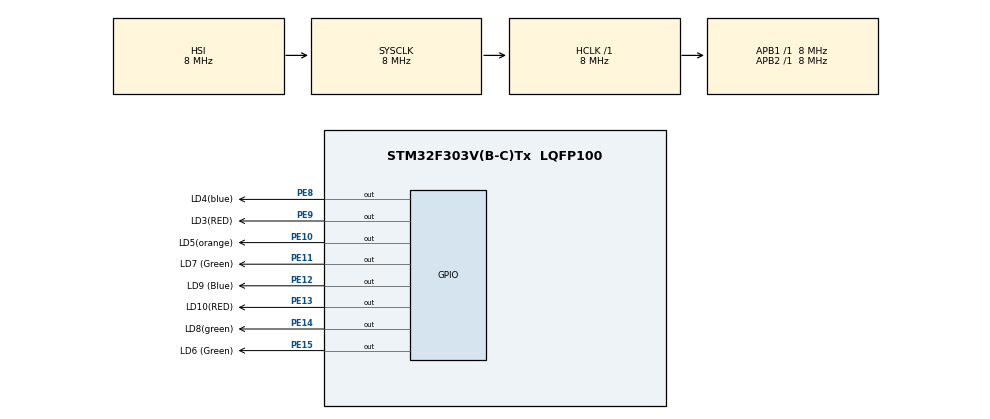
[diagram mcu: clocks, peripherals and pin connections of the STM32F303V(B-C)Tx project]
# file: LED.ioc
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Mcu.Family=STM32F3
Mcu.Name=STM32F303V(B-C)Tx
Mcu.Package=LQFP100
NVIC.PriorityGroup=NVIC_PRIORITYGROUP_4
PE10.GPIO_Label=LD5(orange)
PE10.Signal=GPIO_Output
PE11.GPIO_Label=LD7 (Green)
PE11.Signal=GPIO_Output
PE12.GPIO_Label=LD9 (Blue)
PE12.Signal=GPIO_Output
PE13.GPIO_Label=LD10(RED)
PE13.Signal=GPIO_Output
PE14.GPIO_Label=LD8(green)
PE14.Signal=GPIO_Output
PE15.GPIO_Label=LD6 (Green)
PE15.Signal=GPIO_Output
PE8.GPIO_Label=LD4(blue)
PE8.Signal=GPIO_Output
PE9.GPIO_Label=LD3(RED)
PE9.Signal=GPIO_Output
ProjectManager.HeapSize=0x200
ProjectManager.StackSize=0x400
ProjectManager.TargetToolchain=STM32CubeIDE
RCC.AHBFreq_Value=8000000
RCC.APB1Freq_Value=8000000
RCC.APB2Freq_Value=8000000
RCC.CortexFreq_Value=8000000
RCC.HSE_VALUE=8000000
RCC.HSI_VALUE=8000000
RCC.LSE_VALUE=32768
RCC.SYSCLKFreq_VALUE=8000000
board=custom

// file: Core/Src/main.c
/* USER CODE BEGIN Header */
/**
  ******************************************************************************
  * @file           : main.c
  * @brief          : Main program body
  ******************************************************************************
  * @attention
  *
  * Copyright (c) 2024 STMicroelectronics.
  * All rights reserved.
  *
  * This software is licensed under terms that can be found in the LICENSE file
  * in the root directory of this software component.
  * If no LICENSE file comes with this software, it is provided AS-IS.
  *
  ******************************************************************************
  */
/* USER CODE END Header */
#include "main.h"

void SystemClock_Config(void);
static void MX_GPIO_Init(void);

int main(void)
{
  /* USER CODE BEGIN 1 */
	GPIO_TypeDef* ledPorts[] = {LD3_GPIO_Port, LD4_GPIO_Port, LD6_GPIO_Port, LD8_GPIO_Port, LD10_GPIO_Port, LD9_GPIO_Port, LD7_GPIO_Port, LD5_GPIO_Port};
	    uint16_t ledPins[] = {LD3_Pin, LD4_Pin, LD6_Pin, LD8_Pin, LD10_Pin, LD9_Pin, LD7_Pin, LD5_Pin};

	    int numLeds = sizeof(ledPorts) / sizeof(ledPorts[0]);
  /* USER CODE END 1 */

  /* MCU Configuration--------------------------------------------------------*/

  /* Reset of all peripherals, Initializes the Flash interface and the Systick. */
  HAL_Init();

  /* Configure the system clock */
  SystemClock_Config();

  /* Initialize all configured peripherals */
  MX_GPIO_Init();

  /* Infinite loop */
  while (1)
  {

    /* USER CODE BEGIN 3 */
	  for (int i = 0; i < numLeds; ++i)
	         {
	             HAL_GPIO_TogglePin(ledPorts[i], ledPins[i]);
	             HAL_Delay(500);
	             HAL_GPIO_TogglePin(ledPorts[i], ledPins[i]);  // Turn off the current LED
	             HAL_Delay(500);
	         }
  }
  /* USER CODE END 3 */
}

void SystemClock_Config(void)
{
  RCC_OscInitTypeDef RCC_OscInitStruct = {0};
  RCC_ClkInitTypeDef RCC_ClkInitStruct = {0};

  /** Initializes the RCC Oscillators according to the specified parameters
  * in the RCC_OscInitTypeDef structure.
  */
  RCC_OscInitStruct.OscillatorType = RCC_OSCILLATORTYPE_HSI;
  RCC_OscInitStruct.HSIState = RCC_HSI_ON;
  RCC_OscInitStruct.HSICalibrationValue = RCC_HSICALIBRATION_DEFAULT;
  RCC_OscInitStruct.PLL.PLLState = RCC_PLL_NONE;
  if (HAL_RCC_OscConfig(&RCC_OscInitStruct) != HAL_OK)
  {
    Error_Handler();
  }

  /** Initializes the CPU, AHB and APB buses clocks
  */
  RCC_ClkInitStruct.ClockType = RCC_CLOCKTYPE_HCLK|RCC_CLOCKTYPE_SYSCLK
                              |RCC_CLOCKTYPE_PCLK1|RCC_CLOCKTYPE_PCLK2;
  RCC_ClkInitStruct.SYSCLKSource = RCC_SYSCLKSOURCE_HSI;
  RCC_ClkInitStruct.AHBCLKDivider = RCC_SYSCLK_DIV1;
  RCC_ClkInitStruct.APB1CLKDivider = RCC_HCLK_DIV1;
  RCC_ClkInitStruct.APB2CLKDivider = RCC_HCLK_DIV1;

  if (HAL_RCC_ClockConfig(&RCC_ClkInitStruct, FLASH_LATENCY_0) != HAL_OK)
  {
    Error_Handler();
  }
}

static void MX_GPIO_Init(void)
{
  GPIO_InitTypeDef GPIO_InitStruct = {0};

  /* GPIO Ports Clock Enable */
  __HAL_RCC_GPIOE_CLK_ENABLE();

  /*Configure GPIO pin Output Level */
  HAL_GPIO_WritePin(GPIOE, LD4_Pin|LD3_Pin|LD5_Pin|LD7_Pin
                          |LD9_Pin|LD10_Pin|LD8_Pin|LD6_Pin, GPIO_PIN_RESET);

  /*Configure GPIO pins : LD4_Pin LD3_Pin LD5_Pin LD7_Pin
                           LD9_Pin LD10_Pin LD8_Pin LD6_Pin */
  GPIO_InitStruct.Pin = LD4_Pin|LD3_Pin|LD5_Pin|LD7_Pin
                          |LD9_Pin|LD10_Pin|LD8_Pin|LD6_Pin;
  GPIO_InitStruct.Mode = GPIO_MODE_OUTPUT_PP;
  GPIO_InitStruct.Pull = GPIO_NOPULL;
  GPIO_InitStruct.Speed = GPIO_SPEED_FREQ_LOW;
  HAL_GPIO_Init(GPIOE, &GPIO_InitStruct);

}

void Error_Handler(void)
{
  __disable_irq();
  while (1)
  {
  }
}
